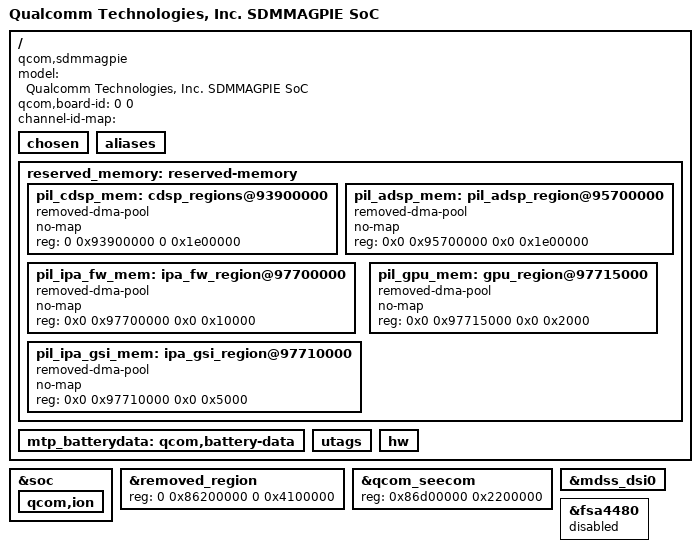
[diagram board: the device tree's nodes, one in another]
/* Copyright (c) 2018, The Linux Foundation. All rights reserved.
 *
 * This program is free software; you can redistribute it and/or modify
 * it under the terms of the GNU General Public License version 2 and
 * only version 2 as published by the Free Software Foundation.
 *
 * This program is distributed in the hope that it will be useful,
 * but WITHOUT ANY WARRANTY; without even the implied warranty of
 * MERCHANTABILITY or FITNESS FOR A PARTICULAR PURPOSE.  See the
 * GNU General Public License for more details.
 */

/dts-v1/;

/dts-v1/;

#include "sdmmagpie.dtsi"

/ {
	model = "Qualcomm Technologies, Inc. SDMMAGPIE SoC";
	compatible = "qcom,sdmmagpie";
	qcom,board-id = <0 0>;
	channel-id-map = "";
/*
 * Some nodes need labels assigned to appear in __symbols__
 */
	chosen: chosen { };
	aliases: aliases { };
	reserved_memory: reserved-memory { };
	mtp_batterydata: qcom,battery-data {};
	utags: utags { };
	hw: hw { };
};

/*
 * reduce cdsp caveout for all targets as it only be used by FOD feature
 * the size in qdsp6.xml need to be changed as well
 */
/delete-node/ &pil_cdsp_mem;
/delete-node/ &pil_adsp_mem;
/delete-node/ &pil_ipa_fw_mem;
/delete-node/ &pil_ipa_gsi_mem;
/delete-node/ &pil_gpu_mem;
/delete-node/ &cdsp_sec_mem;

&reserved_memory {
	pil_cdsp_mem: cdsp_regions@93900000 {
		compatible = "removed-dma-pool";
		no-map;
		reg = <0 0x93900000 0 0x1e00000>;
	};

	pil_adsp_mem: pil_adsp_region@95700000 {
		compatible = "removed-dma-pool";
		no-map;
		reg = <0x0 0x95700000 0x0 0x1e00000>;
	};

	pil_ipa_fw_mem: ipa_fw_region@97700000 {
		compatible = "removed-dma-pool";
		no-map;
		reg = <0x0 0x97700000 0x0 0x10000>;
	};

	pil_ipa_gsi_mem: ipa_gsi_region@97710000 {
		compatible = "removed-dma-pool";
		no-map;
		reg = <0x0 0x97710000 0x0 0x5000>;
	};

	pil_gpu_mem: gpu_region@97715000 {
		compatible = "removed-dma-pool";
		no-map;
		reg = <0x0 0x97715000 0x0 0x2000>;
	};
};

&soc {
	qcom,ion {
		/delete-node/ qcom,ion-heap@14;
	};
};

/*
 * ram reallocation end
 */

&removed_region {
	reg = <0 0x86200000 0 0x4100000>;
};

&qcom_seecom {
	reg = <0x86d00000 0x2200000>;
};


&mdss_dsi0 {
	/delete-property/ qcom,split-link-supported;
};

&fsa4480 {
	status = "disabled";
};
